# TM4C1294NCPDT register map
Vendor: Texas Instruments; File version: 2.2.0.295
CPU: CM4 r0p1, little endian, MPU, FPU, 3 interrupt priority bits
Registers are 32-bit, read-write, no defined reset value unless marked. A register's access mark holds for its fields unless they carry their own. Offsets are from the block's base; [hi:lo] are bit positions; {n}, {i} and the like mark numbered series; 'fields as' and 'values as' point back to an identical list.

## SYSCTL — System Control (SYSCTL)
Base 0x400FE000
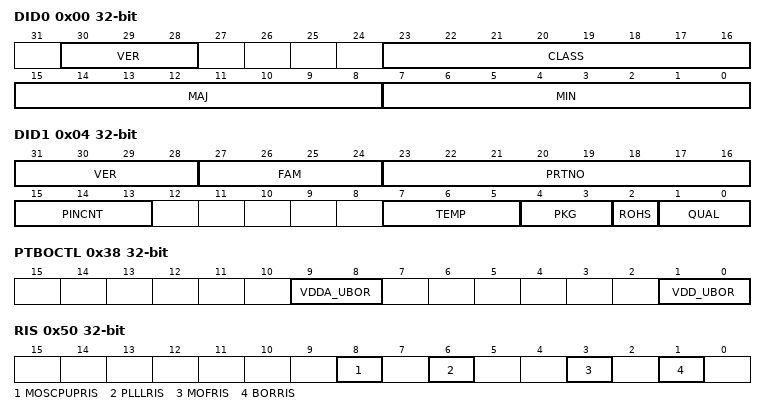
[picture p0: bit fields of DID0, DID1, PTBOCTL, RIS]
0x00 DID0
  [30:28] VER — DID0 Version
    1=Second version of the DID0
  [23:16] CLASS — Device Class
    10=TM4C129 (Tiva(TM) TM4C129-class)
  [15:8] MAJ — Major Revision
    0=REVA (Revision A (initial device)); 1=REVB (Revision B (first base layer); 2=REVC (Revision C (second base layer)
  [7:0] MIN — Minor Revision
    0=Initial device, or a major; 1=First metal layer change; 2=Second metal layer change
0x04 DID1
  [31:28] VER — DID1 Version
    1=fury_ib
  [27:24] FAM — Family
    0=TIVA (Tiva family of microcontollers)
  [23:16] PRTNO — Part Number
    31=TM4C1294NCPDT
  [15:13] PINCNT — Package Pin Count
    2=100-pin LQFP package; 3=64-pin LQFP package; 4=144-pin LQFP package; 5=157-pin BGA package; 6=128-pin TQFP package
  [7:5] TEMP — Temperature Range
    0=C (Commercial temperature range); 1=I (Industrial temperature range); 2=E (Extended temperature range)
  [4:3] PKG — Package Type
    1=QFP (QFP package); 2=BGA (BGA package)
  [2] ROHS — RoHS-Compliance
  [1:0] QUAL — Qualification Status
    0=ES (Engineering Sample (unqualified)); 1=PP (Pilot Production (unqualified)); 2=FQ (Fully Qualified)
0x38 PTBOCTL
  [9:8] VDDA_UBOR — VDDA under BOR Event Action
    0=NONE (No Action); 1=SYSINT (System control interrupt); 2=NMI; 3=RST (Reset)
  [1:0] VDD_UBOR — VDD (VDDS) under BOR Event
    values as VDDA_UBOR
0x50 RIS
  [8] MOSCPUPRIS — MOSC Power Up Raw Interrupt
  [6] PLLLRIS — PLL Lock Raw Interrupt Status
  [3] MOFRIS — Main Oscillator Failure Raw
  [1] BORRIS — Brown-Out Reset Raw Interrupt
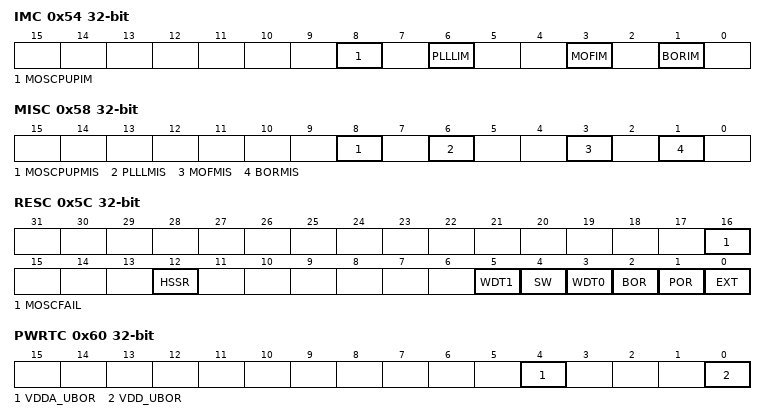
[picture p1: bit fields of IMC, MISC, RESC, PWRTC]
0x54 IMC
  [8] MOSCPUPIM — MOSC Power Up Interrupt Mask
  [6] PLLLIM — PLL Lock Interrupt Mask
  [3] MOFIM — Main Oscillator Failure
  [1] BORIM — Brown-Out Reset Interrupt Mask
0x58 MISC
  [8] MOSCPUPMIS — MOSC Power Up Masked Interrupt
  [6] PLLLMIS — PLL Lock Masked Interrupt Status
  [3] MOFMIS — Main Oscillator Failure Masked
  [1] BORMIS — BOR Masked Interrupt Status
0x5C RESC
  [16] MOSCFAIL — MOSC Failure Reset
  [12] HSSR — HSSR Reset
  [5] WDT1 — Watchdog Timer 1 Reset
  [4] SW — Software Reset
  [3] WDT0 — Watchdog Timer 0 Reset
  [2] BOR — Brown-Out Reset
  [1] POR — Power-On Reset
  [0] EXT — External Reset
0x60 PWRTC
  [4] VDDA_UBOR — VDDA Under BOR Status
  [0] VDD_UBOR — VDD Under BOR Status
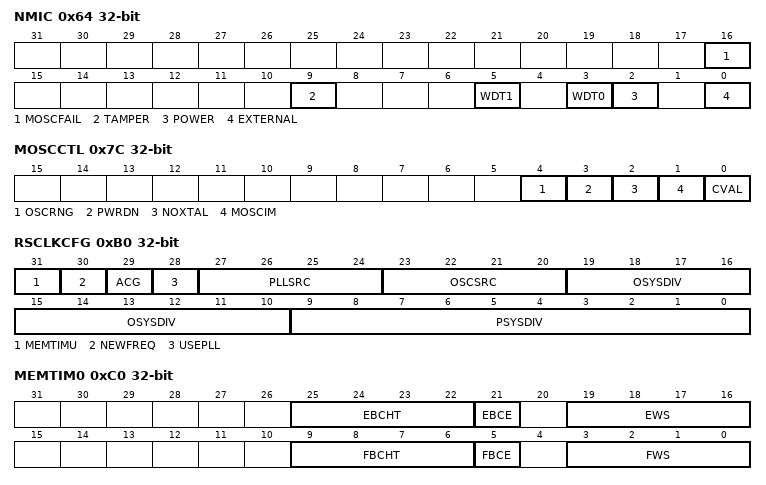
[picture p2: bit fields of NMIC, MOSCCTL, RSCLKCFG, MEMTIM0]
0x64 NMIC
  [16] MOSCFAIL — MOSC Failure NMI
  [9] TAMPER — Tamper Event NMI
  [5] WDT1 — Watch Dog Timer (WDT) 1 NMI
  [3] WDT0 — Watch Dog Timer (WDT) 0 NMI
  [2] POWER — Power/Brown Out Event NMI
  [0] EXTERNAL — External Pin NMI
0x7C MOSCCTL
  [4] OSCRNG — Oscillator Range
  [3] PWRDN — Power Down
  [2] NOXTAL — No Crystal Connected
  [1] MOSCIM — MOSC Failure Action
  [0] CVAL — Clock Validation for MOSC
0xB0 RSCLKCFG
  [31] MEMTIMU — Memory Timing Register Update
  [30] NEWFREQ — New PLLFREQ Accept
  [29] ACG — Auto Clock Gating
  [28] USEPLL
  [27:24] PLLSRC — PLL Source
    0=PIOSC (PIOSC is PLL input clock source); 3=MOSC (MOSC is the PLL input clock)
  [23:20] OSCSRC — Oscillator Source
    0=PIOSC (PIOSC is oscillator source); 2=LFIOSC (LFIOSC is oscillator source); 3=MOSC (MOSC is oscillator source); 4=RTC (Hibernation Module RTC)
  [19:10] OSYSDIV — Oscillator System Clock Divisor
  [9:0] PSYSDIV — PLL System Clock Divisor
0xC0 MEMTIM0
  [25:22] EBCHT — EEPROM Clock High Time
    0=0_5 (1/2 system clock period); 1=1 system clock period; 2=1_5 (1.5 system clock periods); 3=2 system clock periods; 4=2_5 (2.5 system clock periods); 5=3 system clock periods; 6=3_5 (3.5 system clock periods); 7=4 system clock periods; 8=4_5 (4.5 system clock periods)
  [21] EBCE — EEPROM Bank Clock Edge
  [19:16] EWS — EEPROM Wait States
  [9:6] FBCHT — Flash Bank Clock High Time
    values as EBCHT
  [5] FBCE — Flash Bank Clock Edge
  [3:0] FWS — Flash Wait State
0x138 ALTCLKCFG
  [3:0] ALTCLK — Alternate Clock Source
    0=PIOSC; 3=RTCOSC (Hibernation Module Real-time); 4=LFIOSC (Low-frequency internal)
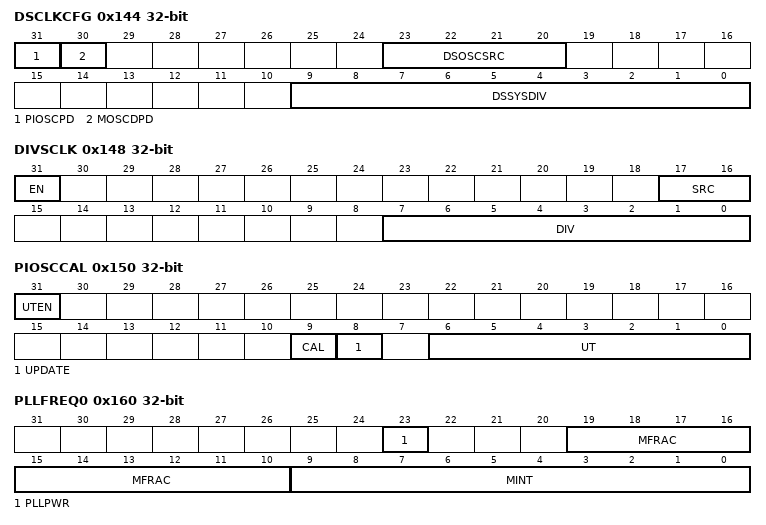
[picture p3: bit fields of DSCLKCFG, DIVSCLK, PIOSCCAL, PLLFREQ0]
0x144 DSCLKCFG
  [31] PIOSCPD — PIOSC Power Down
  [30] MOSCDPD — MOSC Disable Power Down
  [23:20] DSOSCSRC — Deep Sleep Oscillator Source
    0=PIOSC; 2=LFIOSC; 3=MOSC; 4=RTC (Hibernation Module RTCOSC)
  [9:0] DSSYSDIV — Deep Sleep Clock Divisor
0x148 DIVSCLK
  [31] EN — DIVSCLK Enable
  [17:16] SRC — Clock Source
    0=SYSCLK (System Clock); 1=PIOSC; 2=MOSC
  [7:0] DIV — Divisor Value
0x14C SYSPROP
  [0] FPU — FPU Present
0x150 PIOSCCAL
  [31] UTEN — Use User Trim Value
  [9] CAL — Start Calibration
  [8] UPDATE — Update Trim
  [6:0] UT — User Trim Value
0x154 PIOSCSTAT
  [22:16] DT — Default Trim Value
  [9] CRFAIL — The last calibration operation
  [9:8] CR — Calibration Result
  [8] CRPASS — The last calibration operation
  [6:0] CT — Calibration Trim Value
0x160 PLLFREQ0
  [23] PLLPWR — PLL Power
  [19:10] MFRAC — PLL M Fractional Value
  [9:0] MINT — PLL M Integer Value
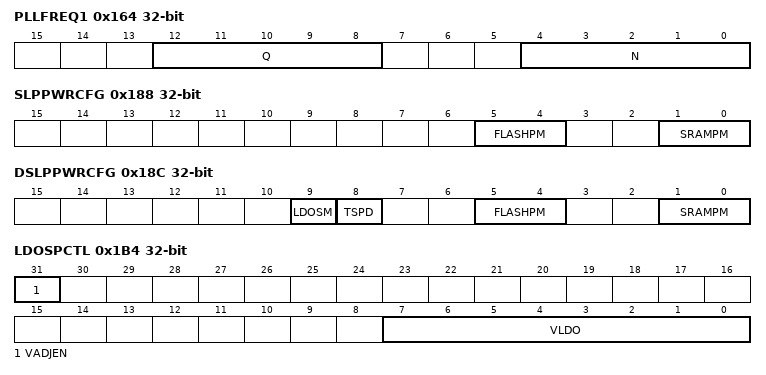
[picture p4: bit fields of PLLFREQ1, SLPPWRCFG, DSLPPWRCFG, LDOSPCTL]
0x164 PLLFREQ1
  [12:8] Q — PLL Q Value
  [4:0] N — PLL N Value
0x168 PLLSTAT
  [0] LOCK — PLL Lock
0x188 SLPPWRCFG
  [5:4] FLASHPM — Flash Power Modes
    0=NRM (Active Mode); 2=SLP (Low Power Mode)
  [1:0] SRAMPM — SRAM Power Modes
    0=NRM (Active Mode); 1=SBY (Standby Mode); 3=LP (Low Power Mode)
0x18C DSLPPWRCFG
  [9] LDOSM — LDO Sleep Mode
  [8] TSPD — Temperature Sense Power Down
  [5:4] FLASHPM — Flash Power Modes
    0=NRM (Active Mode); 2=SLP (Low Power Mode)
  [1:0] SRAMPM — SRAM Power Modes
    values as SLPPWRCFG.SRAMPM
0x1A0 NVMSTAT
  [0] FWB — 32 Word Flash Write Buffer
0x1B4 LDOSPCTL
  [31] VADJEN — Voltage Adjust Enable
  [7:0] VLDO — LDO Output Voltage
    18=0_90V; 19=0_95V; 20=1_00V; 21=1_05V; 22=1_10V; 23=1_15V; 24=1_20V
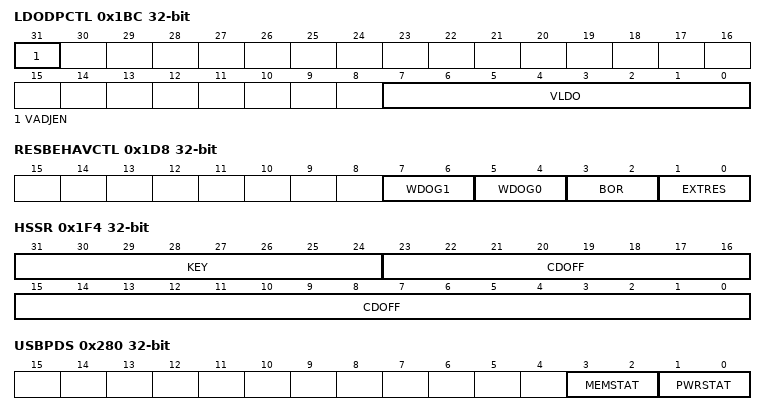
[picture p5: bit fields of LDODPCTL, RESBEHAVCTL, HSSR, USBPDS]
0x1BC LDODPCTL
  [31] VADJEN — Voltage Adjust Enable
  [7:0] VLDO — LDO Output Voltage
    18=0_90V; 19=0_95V; 20=1_00V; 21=1_05V; 22=1_10V; 23=1_15V; 24=1_20V; 25=1_25V; 26=1_30V; 27=1_35V
0x1D8 RESBEHAVCTL
  [7:6] WDOG1 — Watchdog 1 Reset Operation
    2=SYSRST (Watchdog 1 issues a system); 3=POR (Watchdog 1 issues a simulated)
  [5:4] WDOG0 — Watchdog 0 Reset Operation
    2=SYSRST (Watchdog 0 issues a system); 3=POR (Watchdog 0 issues a simulated)
  [3:2] BOR — BOR Reset operation
    2=SYSRST (Brown Out Reset issues system); 3=POR (Brown Out Reset issues a)
  [1:0] EXTRES — External RST Pin Operation
    2=SYSRST (External RST assertion issues a); 3=POR (External RST assertion issues a)
0x1F4 HSSR
  [31:24] KEY — Write Key
  [23:0] CDOFF — Command Descriptor Pointer
0x280 USBPDS
  [3:2] MEMSTAT — Memory Array Power Status
    0=OFF (Array OFF); 1=RETAIN (SRAM Retention); 3=ON (Array On)
  [1:0] PWRSTAT — Power Domain Status
    0=OFF; 3=ON
0x284 USBMPC
  [1:0] PWRCTL — Memory Array Power Control
    values as USBPDS.MEMSTAT
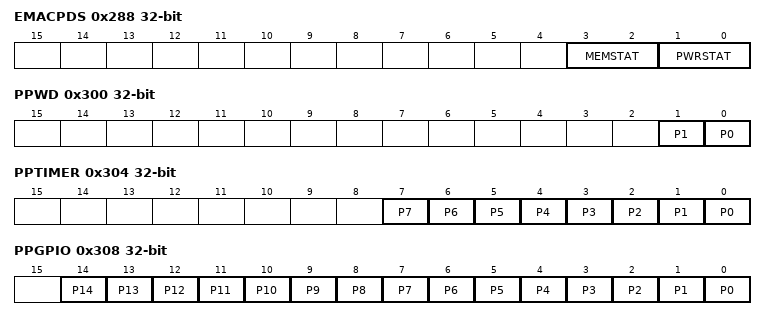
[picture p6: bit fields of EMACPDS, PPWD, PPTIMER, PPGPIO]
0x288 EMACPDS
  [3:2] MEMSTAT — Memory Array Power Status
    0=OFF (Array OFF); 3=ON (Array On)
  [1:0] PWRSTAT — Power Domain Status
    0=OFF; 3=ON
0x28C EMACMPC
  [1:0] PWRCTL — Memory Array Power Control
    0=OFF (Array OFF); 3=ON (Array On)
0x300 PPWD
  [1] P1 — Watchdog Timer 1 Present
  [0] P0 — Watchdog Timer 0 Present
0x304 PPTIMER
  [n] P{n} (n=0..7) — 16/32-Bit General-Purpose Timer
0x308 PPGPIO
  [14] P14 — GPIO Port Q Present
  [13] P13 — GPIO Port P Present
  [12] P12 — GPIO Port N Present
  [11] P11 — GPIO Port M Present
  [10] P10 — GPIO Port L Present
  [9] P9 — GPIO Port K Present
  [8] P8 — GPIO Port J Present
  [7] P7 — GPIO Port H Present
  [6] P6 — GPIO Port G Present
  [5] P5 — GPIO Port F Present
  [4] P4 — GPIO Port E Present
  [3] P3 — GPIO Port D Present
  [2] P2 — GPIO Port C Present
  [1] P1 — GPIO Port B Present
  [0] P0 — GPIO Port A Present
0x30C PPDMA
  [0] P0 — uDMA Module Present
0x310 PPEPI
  [0] P0 — EPI Module Present
0x314 PPHIB
  [0] P0 — Hibernation Module Present
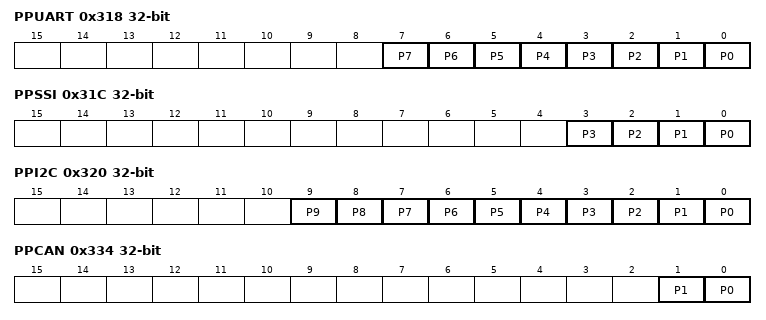
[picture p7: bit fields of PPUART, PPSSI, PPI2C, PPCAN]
0x318 PPUART
  [n] P{n} (n=0..7) — UART Module {n} Present
0x31C PPSSI
  [n] P{n} (n=0..3) — SSI Module {n} Present
0x320 PPI2C
  [n] P{n} (n=0..9) — I2C Module {n} Present
0x328 PPUSB
  [0] P0 — USB Module Present
0x330 PPEPHY
  [0] P0 — Ethernet PHY Module Present
0x334 PPCAN
  [1] P1 — CAN Module 1 Present
  [0] P0 — CAN Module 0 Present
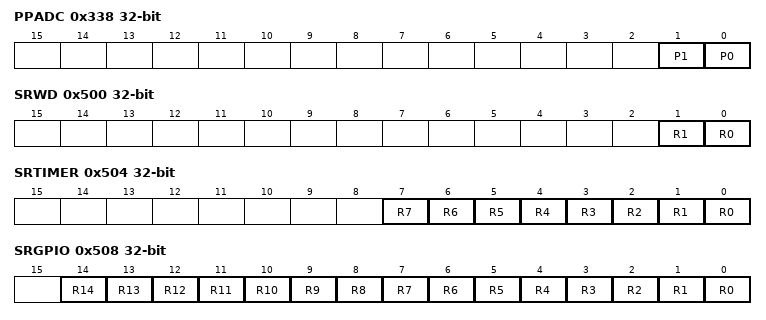
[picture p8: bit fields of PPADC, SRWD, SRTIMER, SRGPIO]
0x338 PPADC
  [1] P1 — ADC Module 1 Present
  [0] P0 — ADC Module 0 Present
0x33C PPACMP
  [0] P0 — Analog Comparator Module Present
0x340 PPPWM
  [0] P0 — PWM Module 0 Present
0x344 PPQEI
  [0] P0 — QEI Module 0 Present
0x348 PPLPC
  [0] P0 — LPC Module Present
0x350 PPPECI
  [0] P0 — PECI Module Present
0x354 PPFAN
  [0] P0 — FAN Module 0 Present
0x358 PPEEPROM
  [0] P0 — EEPROM Module Present
0x35C PPWTIMER
  [0] P0 — 32/64-Bit Wide General-Purpose
0x370 PPRTS
  [0] P0 — RTS Module Present
0x374 PPCCM
  [0] P0 — CRC and Cryptographic Modules
0x390 PPLCD
  [0] P0 — LCD Module Present
0x398 PPOWIRE
  [0] P0 — 1-Wire Module Present
0x39C PPEMAC
  [0] P0 — Ethernet Controller Module
0x3A4 PPHIM
  [0] P0 — HIM Module Present
0x500 SRWD
  [1] R1 — Watchdog Timer 1 Software Reset
  [0] R0 — Watchdog Timer 0 Software Reset
0x504 SRTIMER
  [n] R{n} (n=0..7) — 16/32-Bit General-Purpose Timer
0x508 SRGPIO
  [14] R14 — GPIO Port Q Software Reset
  [13] R13 — GPIO Port P Software Reset
  [12] R12 — GPIO Port N Software Reset
  [11] R11 — GPIO Port M Software Reset
  [10] R10 — GPIO Port L Software Reset
  [9] R9 — GPIO Port K Software Reset
  [8] R8 — GPIO Port J Software Reset
  [7] R7 — GPIO Port H Software Reset
  [6] R6 — GPIO Port G Software Reset
  [5] R5 — GPIO Port F Software Reset
  [4] R4 — GPIO Port E Software Reset
  [3] R3 — GPIO Port D Software Reset
  [2] R2 — GPIO Port C Software Reset
  [1] R1 — GPIO Port B Software Reset
  [0] R0 — GPIO Port A Software Reset
0x50C SRDMA
  [0] R0 — uDMA Module Software Reset
0x510 SREPI
  [0] R0 — EPI Module Software Reset
0x514 SRHIB
  [0] R0 — Hibernation Module Software
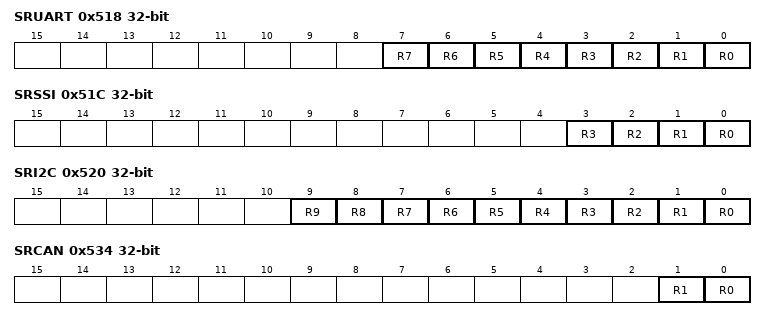
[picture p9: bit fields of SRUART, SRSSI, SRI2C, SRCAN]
0x518 SRUART
  [n] R{n} (n=0..7) — UART Module {n} Software Reset
0x51C SRSSI
  [n] R{n} (n=0..3) — SSI Module {n} Software Reset
0x520 SRI2C
  [n] R{n} (n=0..9) — I2C Module {n} Software Reset
0x528 SRUSB
  [0] R0 — USB Module Software Reset
0x530 SREPHY
  [0] R0 — Ethernet PHY Module Software
0x534 SRCAN
  [1] R1 — CAN Module 1 Software Reset
  [0] R0 — CAN Module 0 Software Reset
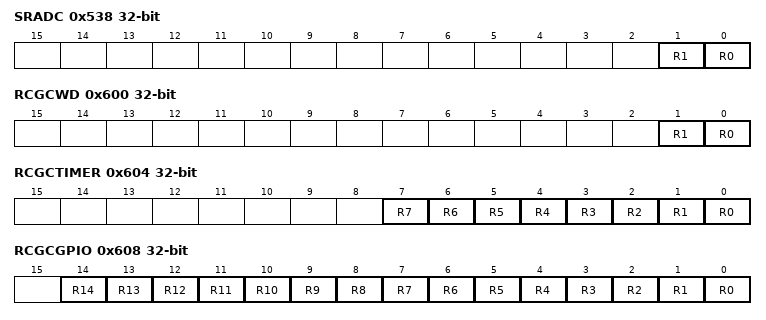
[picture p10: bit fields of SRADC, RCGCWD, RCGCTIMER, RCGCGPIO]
0x538 SRADC
  [1] R1 — ADC Module 1 Software Reset
  [0] R0 — ADC Module 0 Software Reset
0x53C SRACMP
  [0] R0 — Analog Comparator Module 0
0x540 SRPWM
  [0] R0 — PWM Module 0 Software Reset
0x544 SRQEI
  [0] R0 — QEI Module 0 Software Reset
0x558 SREEPROM
  [0] R0 — EEPROM Module Software Reset
0x574 SRCCM
  [0] R0 — CRC and Cryptographic Modules
0x59C SREMAC
  [0] R0 — Ethernet Controller MAC Module 0
0x600 RCGCWD
  [1] R1 — Watchdog Timer 1 Run Mode Clock
  [0] R0 — Watchdog Timer 0 Run Mode Clock
0x604 RCGCTIMER
  [n] R{n} (n=0..7) — 16/32-Bit General-Purpose Timer
0x608 RCGCGPIO
  [14] R14 — GPIO Port Q Run Mode Clock
  [13] R13 — GPIO Port P Run Mode Clock
  [12] R12 — GPIO Port N Run Mode Clock
  [11] R11 — GPIO Port M Run Mode Clock
  [10] R10 — GPIO Port L Run Mode Clock
  [9] R9 — GPIO Port K Run Mode Clock
  [8] R8 — GPIO Port J Run Mode Clock
  [7] R7 — GPIO Port H Run Mode Clock
  [6] R6 — GPIO Port G Run Mode Clock
  [5] R5 — GPIO Port F Run Mode Clock
  [4] R4 — GPIO Port E Run Mode Clock
  [3] R3 — GPIO Port D Run Mode Clock
  [2] R2 — GPIO Port C Run Mode Clock
  [1] R1 — GPIO Port B Run Mode Clock
  [0] R0 — GPIO Port A Run Mode Clock
0x60C RCGCDMA
  [0] R0 — uDMA Module Run Mode Clock
0x610 RCGCEPI
  [0] R0 — EPI Module Run Mode Clock Gating
0x614 RCGCHIB
  [0] R0 — Hibernation Module Run Mode
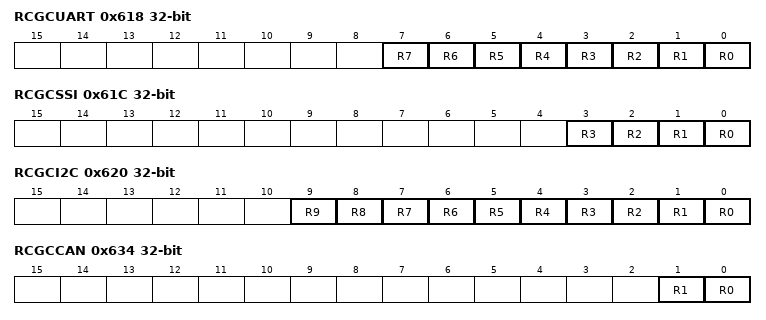
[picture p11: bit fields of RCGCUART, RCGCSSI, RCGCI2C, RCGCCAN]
0x618 RCGCUART
  [n] R{n} (n=0..7) — UART Module {n} Run Mode Clock
0x61C RCGCSSI
  [n] R{n} (n=0..3) — SSI Module {n} Run Mode Clock
0x620 RCGCI2C
  [n] R{n} (n=0..9) — I2C Module {n} Run Mode Clock
0x628 RCGCUSB
  [0] R0 — USB Module Run Mode Clock Gating
0x630 RCGCEPHY
  [0] R0 — Ethernet PHY Module Run Mode
0x634 RCGCCAN
  [1] R1 — CAN Module 1 Run Mode Clock
  [0] R0 — CAN Module 0 Run Mode Clock
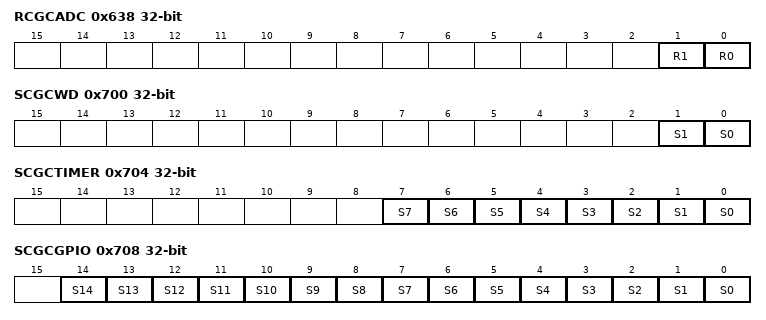
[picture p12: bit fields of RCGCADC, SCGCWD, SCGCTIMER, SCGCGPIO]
0x638 RCGCADC
  [1] R1 — ADC Module 1 Run Mode Clock
  [0] R0 — ADC Module 0 Run Mode Clock
0x63C RCGCACMP
  [0] R0 — Analog Comparator Module 0 Run
0x640 RCGCPWM
  [0] R0 — PWM Module 0 Run Mode Clock
0x644 RCGCQEI
  [0] R0 — QEI Module 0 Run Mode Clock
0x658 RCGCEEPROM
  [0] R0 — EEPROM Module Run Mode Clock
0x674 RCGCCCM
  [0] R0 — CRC and Cryptographic Modules
0x69C RCGCEMAC
  [0] R0 — Ethernet MAC Module 0 Run Mode
0x700 SCGCWD
  [1] S1 — Watchdog Timer 1 Sleep Mode
  [0] S0 — Watchdog Timer 0 Sleep Mode
0x704 SCGCTIMER
  [n] S{n} (n=0..7) — 16/32-Bit General-Purpose Timer
0x708 SCGCGPIO
  [14] S14 — GPIO Port Q Sleep Mode Clock
  [13] S13 — GPIO Port P Sleep Mode Clock
  [12] S12 — GPIO Port N Sleep Mode Clock
  [11] S11 — GPIO Port M Sleep Mode Clock
  [10] S10 — GPIO Port L Sleep Mode Clock
  [9] S9 — GPIO Port K Sleep Mode Clock
  [8] S8 — GPIO Port J Sleep Mode Clock
  [7] S7 — GPIO Port H Sleep Mode Clock
  [6] S6 — GPIO Port G Sleep Mode Clock
  [5] S5 — GPIO Port F Sleep Mode Clock
  [4] S4 — GPIO Port E Sleep Mode Clock
  [3] S3 — GPIO Port D Sleep Mode Clock
  [2] S2 — GPIO Port C Sleep Mode Clock
  [1] S1 — GPIO Port B Sleep Mode Clock
  [0] S0 — GPIO Port A Sleep Mode Clock
0x70C SCGCDMA
  [0] S0 — uDMA Module Sleep Mode Clock
0x710 SCGCEPI
  [0] S0 — EPI Module Sleep Mode Clock
0x714 SCGCHIB
  [0] S0 — Hibernation Module Sleep Mode
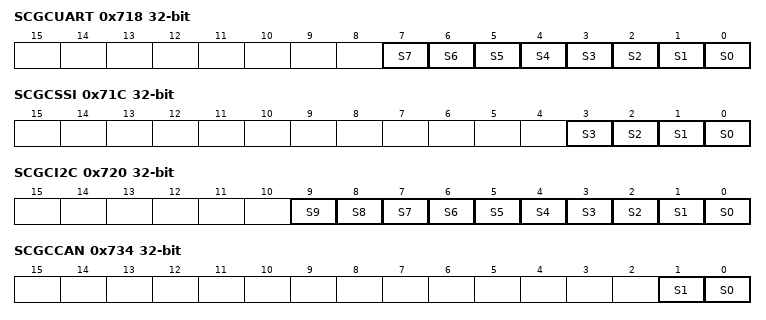
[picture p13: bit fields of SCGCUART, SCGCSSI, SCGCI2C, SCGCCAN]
0x718 SCGCUART
  [n] S{n} (n=0..7) — UART Module {n} Sleep Mode Clock
0x71C SCGCSSI
  [n] S{n} (n=0..3) — SSI Module {n} Sleep Mode Clock
0x720 SCGCI2C
  [n] S{n} (n=0..9) — I2C Module {n} Sleep Mode Clock
0x728 SCGCUSB
  [0] S0 — USB Module Sleep Mode Clock
0x730 SCGCEPHY
  [0] S0 — PHY Module Sleep Mode Clock
0x734 SCGCCAN
  [1] S1 — CAN Module 1 Sleep Mode Clock
  [0] S0 — CAN Module 0 Sleep Mode Clock
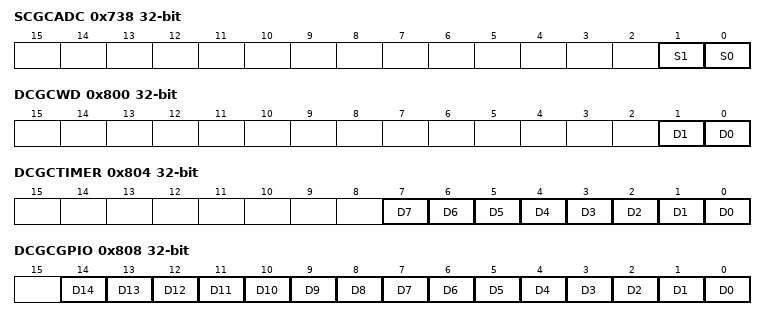
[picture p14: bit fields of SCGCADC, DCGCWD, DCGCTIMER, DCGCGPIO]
0x738 SCGCADC
  [1] S1 — ADC Module 1 Sleep Mode Clock
  [0] S0 — ADC Module 0 Sleep Mode Clock
0x73C SCGCACMP
  [0] S0 — Analog Comparator Module 0 Sleep
0x740 SCGCPWM
  [0] S0 — PWM Module 0 Sleep Mode Clock
0x744 SCGCQEI
  [0] S0 — QEI Module 0 Sleep Mode Clock
0x758 SCGCEEPROM
  [0] S0 — EEPROM Module Sleep Mode Clock
0x774 SCGCCCM
  [0] S0 — CRC and Cryptographic Modules
0x79C SCGCEMAC
  [0] S0 — Ethernet MAC Module 0 Sleep Mode
0x800 DCGCWD
  [1] D1 — Watchdog Timer 1 Deep-Sleep Mode
  [0] D0 — Watchdog Timer 0 Deep-Sleep Mode
0x804 DCGCTIMER
  [n] D{n} (n=0..7) — 16/32-Bit General-Purpose Timer
0x808 DCGCGPIO
  [14] D14 — GPIO Port Q Deep-Sleep Mode
  [13] D13 — GPIO Port P Deep-Sleep Mode
  [12] D12 — GPIO Port N Deep-Sleep Mode
  [11] D11 — GPIO Port M Deep-Sleep Mode
  [10] D10 — GPIO Port L Deep-Sleep Mode
  [9] D9 — GPIO Port K Deep-Sleep Mode
  [8] D8 — GPIO Port J Deep-Sleep Mode
  [7] D7 — GPIO Port H Deep-Sleep Mode
  [6] D6 — GPIO Port G Deep-Sleep Mode
  [5] D5 — GPIO Port F Deep-Sleep Mode
  [4] D4 — GPIO Port E Deep-Sleep Mode
  [3] D3 — GPIO Port D Deep-Sleep Mode
  [2] D2 — GPIO Port C Deep-Sleep Mode
  [1] D1 — GPIO Port B Deep-Sleep Mode
  [0] D0 — GPIO Port A Deep-Sleep Mode
0x80C DCGCDMA
  [0] D0 — uDMA Module Deep-Sleep Mode
0x810 DCGCEPI
  [0] D0 — EPI Module Deep-Sleep Mode Clock
0x814 DCGCHIB
  [0] D0 — Hibernation Module Deep-Sleep
0x818 DCGCUART
  [n] D{n} (n=0..7) — UART Module {n} Deep-Sleep Mode
0x81C DCGCSSI
  [n] D{n} (n=0..3) — SSI Module {n} Deep-Sleep Mode
0x820 DCGCI2C
  [n] D{n} (n=0..9) — I2C Module {n} Deep-Sleep Mode
0x828 DCGCUSB
  [0] D0 — USB Module Deep-Sleep Mode Clock
0x830 DCGCEPHY
  [0] D0 — PHY Module Deep-Sleep Mode Clock
0x834 DCGCCAN
  [1] D1 — CAN Module 1 Deep-Sleep Mode
  [0] D0 — CAN Module 0 Deep-Sleep Mode
0x838 DCGCADC
  [1] D1 — ADC Module 1 Deep-Sleep Mode
  [0] D0 — ADC Module 0 Deep-Sleep Mode
0x83C DCGCACMP
  [0] D0 — Analog Comparator Module 0
0x840 DCGCPWM
  [0] D0 — PWM Module 0 Deep-Sleep Mode
0x844 DCGCQEI
  [0] D0 — QEI Module 0 Deep-Sleep Mode
0x858 DCGCEEPROM
  [0] D0 — EEPROM Module Deep-Sleep Mode
0x874 DCGCCCM
  [0] D0 — CRC and Cryptographic Modules
0x89C DCGCEMAC
  [0] D0 — Ethernet MAC Module 0 Deep-Sleep
0x900 PCWD
  [1] P1 — Watchdog Timer 1 Power Control
  [0] P0 — Watchdog Timer 0 Power Control
0x904 PCTIMER
  [n] P{n} (n=0..7) — General-Purpose Timer {n} Power
0x908 PCGPIO
  [14] P14 — GPIO Port Q Power Control
  [13] P13 — GPIO Port P Power Control
  [12] P12 — GPIO Port N Power Control
  [11] P11 — GPIO Port M Power Control
  [10] P10 — GPIO Port L Power Control
  [9] P9 — GPIO Port K Power Control
  [8] P8 — GPIO Port J Power Control
  [7] P7 — GPIO Port H Power Control
  [6] P6 — GPIO Port G Power Control
  [5] P5 — GPIO Port F Power Control
  [4] P4 — GPIO Port E Power Control
  [3] P3 — GPIO Port D Power Control
  [2] P2 — GPIO Port C Power Control
  [1] P1 — GPIO Port B Power Control
  [0] P0 — GPIO Port A Power Control
0x90C PCDMA
  [0] P0 — uDMA Module Power Control
0x910 PCEPI
  [0] P0 — EPI Module Power Control
0x914 PCHIB
  [0] P0 — Hibernation Module Power Control
0x918 PCUART
  [n] P{n} (n=0..7) — UART Module {n} Power Control
0x91C PCSSI
  [n] P{n} (n=0..3) — SSI Module {n} Power Control
0x920 PCI2C
  [n] P{n} (n=0..9) — I2C Module {n} Power Control
0x928 PCUSB
  [0] P0 — USB Module Power Control
0x930 PCEPHY
  [0] P0 — Ethernet PHY Module Power
0x934 PCCAN
  [1] P1 — CAN Module 1 Power Control
  [0] P0 — CAN Module 0 Power Control
0x938 PCADC
  [1] P1 — ADC Module 1 Power Control
  [0] P0 — ADC Module 0 Power Control
0x93C PCACMP
  [0] P0 — Analog Comparator Module 0 Power
0x940 PCPWM
  [0] P0 — PWM Module 0 Power Control
0x944 PCQEI
  [0] P0 — QEI Module 0 Power Control
0x958 PCEEPROM
  [0] P0 — EEPROM Module 0 Power Control
0x974 PCCCM
  [0] P0 — CRC and Cryptographic Modules
0x99C PCEMAC
  [0] P0 — Ethernet MAC Module 0 Power
0xA00 PRWD
  [1] R1 — Watchdog Timer 1 Peripheral
  [0] R0 — Watchdog Timer 0 Peripheral
0xA04 PRTIMER
  [n] R{n} (n=0..7) — 16/32-Bit General-Purpose Timer
0xA08 PRGPIO
  [14] R14 — GPIO Port Q Peripheral Ready
  [13] R13 — GPIO Port P Peripheral Ready
  [12] R12 — GPIO Port N Peripheral Ready
  [11] R11 — GPIO Port M Peripheral Ready
  [10] R10 — GPIO Port L Peripheral Ready
  [9] R9 — GPIO Port K Peripheral Ready
  [8] R8 — GPIO Port J Peripheral Ready
  [7] R7 — GPIO Port H Peripheral Ready
  [6] R6 — GPIO Port G Peripheral Ready
  [5] R5 — GPIO Port F Peripheral Ready
  [4] R4 — GPIO Port E Peripheral Ready
  [3] R3 — GPIO Port D Peripheral Ready
  [2] R2 — GPIO Port C Peripheral Ready
  [1] R1 — GPIO Port B Peripheral Ready
  [0] R0 — GPIO Port A Peripheral Ready
0xA0C PRDMA
  [0] R0 — uDMA Module Peripheral Ready
0xA10 PREPI
  [0] R0 — EPI Module Peripheral Ready
0xA14 PRHIB
  [0] R0 — Hibernation Module Peripheral
0xA18 PRUART
  [n] R{n} (n=0..7) — UART Module {n} Peripheral Ready
0xA1C PRSSI
  [n] R{n} (n=0..3) — SSI Module {n} Peripheral Ready
0xA20 PRI2C
  [n] R{n} (n=0..9) — I2C Module {n} Peripheral Ready
0xA28 PRUSB
  [0] R0 — USB Module Peripheral Ready
0xA30 PREPHY
  [0] R0 — Ethernet PHY Module Peripheral
0xA34 PRCAN
  [1] R1 — CAN Module 1 Peripheral Ready
  [0] R0 — CAN Module 0 Peripheral Ready
0xA38 PRADC
  [1] R1 — ADC Module 1 Peripheral Ready
  [0] R0 — ADC Module 0 Peripheral Ready
0xA3C PRACMP
  [0] R0 — Analog Comparator Module 0
0xA40 PRPWM
  [0] R0 — PWM Module 0 Peripheral Ready
0xA44 PRQEI
  [0] R0 — QEI Module 0 Peripheral Ready
0xA58 PREEPROM
  [0] R0 — EEPROM Module Peripheral Ready
0xA74 PRCCM
  [0] R0 — CRC and Cryptographic Modules
0xA9C PREMAC
  [0] R0 — Ethernet MAC Module 0 Peripheral
